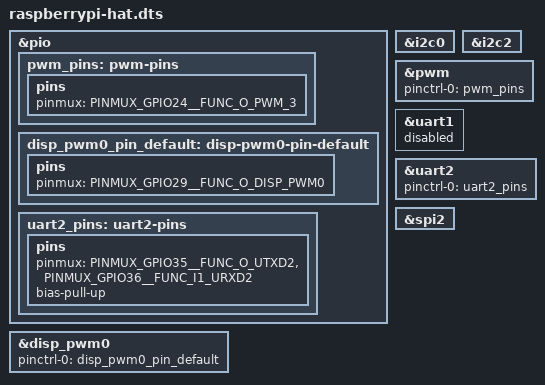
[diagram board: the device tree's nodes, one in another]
/dts-v1/;
/plugin/;

#include <dt-bindings/gpio/gpio.h>
#include <dt-bindings/pinctrl/mediatek,mt8188-pinfunc.h>

/ {
	fragment@0 {
		target = <&pio>;
		__overlay__ {
			pwm_pins: pwm-pins {
				pins {
					pinmux = <PINMUX_GPIO24__FUNC_O_PWM_3>;
				};
			};

			disp_pwm0_pin_default: disp-pwm0-pin-default {
				pins {
					pinmux = <PINMUX_GPIO29__FUNC_O_DISP_PWM0>;
				};
			};

			uart2_pins: uart2-pins {
				pins {
					pinmux = <PINMUX_GPIO35__FUNC_O_UTXD2>,
						 <PINMUX_GPIO36__FUNC_I1_URXD2>;
					bias-pull-up;
				};
			};
		};
	};

	fragment@1 {
		target = <&i2c0>;
		__overlay__ {
			status = "okay";
		};
	};

	fragment@2 {
		target = <&i2c2>;
		__overlay__ {
			status = "okay";
		};
	};

	fragment@3 {
		target = <&disp_pwm0>;
		__overlay__ {
			pinctrl-0 = <&disp_pwm0_pin_default>;
			pinctrl-names = "default";
			status = "okay";
		};
	};

	fragment@4 {
		target = <&pwm>;
		__overlay__ {
			pinctrl-0 = <&pwm_pins>;
			pinctrl-names = "default";
			status = "okay";
		};
	};

	fragment@5 {
		target = <&uart1>;
		__overlay__ {
			status = "disabled";
		};
	};

	fragment@6 {
		target = <&uart2>;
		__overlay__ {
			pinctrl-0 = <&uart2_pins>;
			pinctrl-names = "default";
			status = "okay";
		};
	};

	fragment@7 {
		target = <&spi2>;
		__overlay__ {
			status = "okay";
		};
	};
};
